# ATSAM4E16C register map
Vendor: Atmel; Series: SAM4E; File version: 0
Atmel ATSAM4E16C Microcontroller
CPU: CM4 r0p1, selectable endian, MPU, FPU, 4 interrupt priority bits
Registers are 32-bit, read-write, reset 0x0 unless marked. A register's access mark holds for its fields unless they carry their own. Offsets are from the block's base; lines under a group give offsets from that group; [hi:lo] are bit positions; {n}, {i} and the like mark numbered series; 'fields as' and 'values as' point back to an identical list; <NAME> marks a mode.

## Memory map
0x40000000 PWM size 0x4000 — Pulse Width Modulation Controller
0x40004000 AES size 0x4000 — Advanced Encryption Standard
0x4000D000 MPU size 0x830 — Memory Protection Unit (MPU)
0x40010000 CAN0 size 0x4000 — Controller Area Network 0
0x40034000 GMAC size 0x4000 — Gigabit Ethernet MAC
0x40060600 UART1 size 0x200 — Universal Asynchronous Receiver Transmitter 1
0x40080000 HSMCI size 0x4000 — High Speed MultiMedia Card Interface
0x40084000 UDP size 0x4000 — USB Device Port
0x40088000 SPI size 0x4000 — Serial Peripheral Interface
0x40090000 TC0 size 0x4000 — Timer Counter 0
0x400A0000 USART0 size 0x4000 — Universal Synchronous Asynchronous Receiver Transmitter 0
0x400A4000 USART1 size 0x4000 — Universal Synchronous Asynchronous Receiver Transmitter 1
0x400A8000 TWI0 size 0x8000 — Two-wire Interface 0
0x400AC000 TWI1 size 0x8000 — Two-wire Interface 1
0x400B0000 AFEC0 size 0x4000 — Analog-Front-End Controller 0
0x400B4000 AFEC1 size 0x4000 — Analog-Front-End Controller 1
0x400B8000 DACC size 0x4000 — Digital-to-Analog Converter Controller
0x400BC000 ACC size 0x4000 — Analog Comparator Controller
0x400C0000 DMAC size 0x4000 — DMA Controller
0x400C4000 CMCC size 0x4000 — Cortex M Cache Controller
0x400E0200 MATRIX size 0x200 — AHB Bus Matrix
0x400E0400 PMC size 0x140 — Power Management Controller
0x400E0600 UART0 size 0x128 — Universal Asynchronous Receiver Transmitter 0
0x400E0740 CHIPID size 0x200 — Chip Identifier
0x400E0A00 EFC size 0x200 — Embedded Flash Controller
0x400E0E00 PIOA size 0x200 — Parallel Input/Output Controller A
0x400E1000 PIOB size 0x200 — Parallel Input/Output Controller B
0x400E1400 PIOD size 0x200 — Parallel Input/Output Controller D
0x400E1800 RSTC size 0x200 — Reset Controller
0x400E1810 SUPC size 0x200 — Supply Controller
0x400E1830 RTT size 0x200 — Real-time Timer
0x400E1850 WDT size 0x200 — Watchdog Timer
0x400E1860 RTC size 0x200 — Real-time Clock
0x400E1890 GPBR size 0x200 — General Purpose Backup Registers
0x400E1900 RSWDT size 0x200 — Reinforced Safety Watchdog Timer
0xE000E000 SCB blocks up to offset 0xD40 — System Control Block (SCB)
0xE000E010 SYST size 0x10 — System timer, SysTick
0xE000E100 NVIC size 0xE04 — Nested Vectored Interrupt Controller (NVIC)
0xE000EF34 FPU size 0x10 — Floating Point Unit (FPU)

## Interrupts
3 INT_Hard_Fault (SCB)
4 INT_Mem_Manage_Fault (SCB)
5 INT_Bus_Fault (SCB)
5 PMC
6 EFC
6 INT_Usage_Fault (SCB)
7 UART0
9 PIOA
10 PIOB
11 INT_SVCall (SCB)
12 PIOD
14 INT_PendableSrvReq (SCB)
14 USART0
15 INT_SysTick (SYST)
15 USART1
16 HSMCI
17 TWI0
18 TWI1
19 SPI
20 DMAC
21 TC0
22 TC1 (TC0)
23 TC2 (TC0)
30 AFEC0
31 AFEC1
32 DACC
33 ACC
35 UDP
36 PWM
37 CAN0
39 AES
44 GMAC
45 UART1

## AES — Advanced Encryption Standard
Base 0x40004000; register names take the prefix AES_
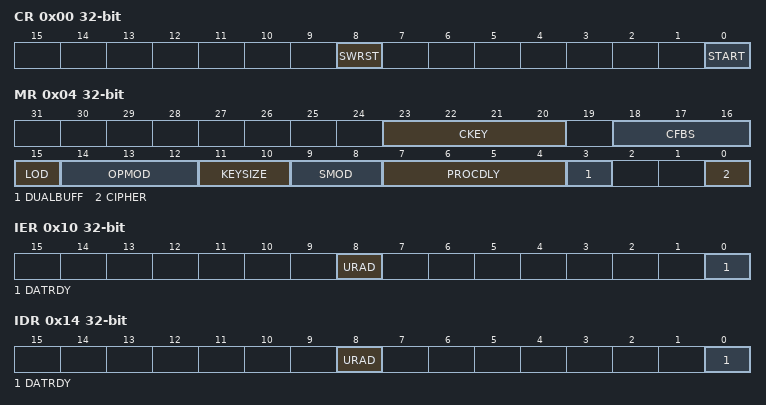
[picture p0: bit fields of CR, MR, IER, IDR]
0x00 CR wo reset not defined — Control Register
  [8] SWRST — Software Reset
  [0] START — Start Processing
0x04 MR — Mode Register
  [23:20] CKEY — Key
    14=PASSWD (This field must be written with 0xE the first time that AES_MR is programmed. For subsequent programming of the AES_MR register, any value can be written, including that of 0xE.Always reads as 0.)
  [18:16] CFBS — Cipher Feedback Data Size
    0=SIZE_128BIT (128-bit); 1=SIZE_64BIT (64-bit); 2=SIZE_32BIT (32-bit); 3=SIZE_16BIT (16-bit); 4=SIZE_8BIT (8-bit)
  [15] LOD — Last Output Data Mode
  [14:12] OPMOD — Operation Mode
    0=ECB (ECB: Electronic Code Book mode); 1=CBC (CBC: Cipher Block Chaining mode); 2=OFB (OFB: Output Feedback mode); 3=CFB (CFB: Cipher Feedback mode); 4=CTR (CTR: Counter mode (16-bit internal counter))
  [11:10] KEYSIZE
    0=AES128 (AES Key Size is 128 bits); 1=AES192 (AES Key Size is 192 bits); 2=AES256 (AES Key Size is 256 bits)
  [9:8] SMOD — Start Mode
    0=MANUAL_START (Manual Mode); 1=AUTO_START (Auto Mode); 2=IDATAR0_START (AES_IDATAR0 access only Auto Mode)
  [7:4] PROCDLY — Processing Delay
  [3] DUALBUFF — Dual Input BUFFer
    0=INACTIVE (AES_IDATARx cannot be written during processing of previous block.); 1=ACTIVE (AES_IDATARx can be written during processing of previous block when SMOD = 0x2. It speeds up the overall runtime of large files.)
  [0] CIPHER — Processing Mode
0x10 IER wo reset not defined — Interrupt Enable Register
  [8] URAD — Unspecified Register Access Detection Interrupt Enable
  [0] DATRDY — Data Ready Interrupt Enable
0x14 IDR wo reset not defined — Interrupt Disable Register
  [8] URAD — Unspecified Register Access Detection Interrupt Disable
  [0] DATRDY — Data Ready Interrupt Disable
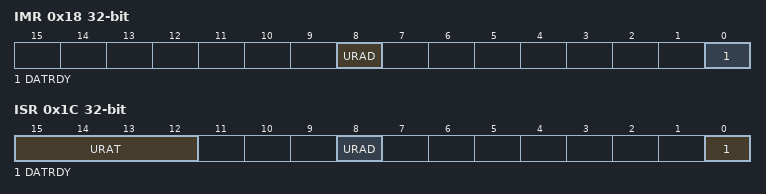
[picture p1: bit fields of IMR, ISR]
0x18 IMR ro — Interrupt Mask Register
  [8] URAD — Unspecified Register Access Detection Interrupt Mask
  [0] DATRDY — Data Ready Interrupt Mask
0x1C ISR ro — Interrupt Status Register
  [15:12] URAT — Unspecified Register Access:
    0=IDR_WR_PROCESSING (Input Data Register written during the data processing when SMOD=0x2 mode.); 1=ODR_RD_PROCESSING (Output Data Register read during the data processing.); 2=MR_WR_PROCESSING (Mode Register written during the data processing.); 3=ODR_RD_SUBKGEN (Output Data Register read during the sub-keys generation.); 4=MR_WR_SUBKGEN (Mode Register written during the sub-keys generation.); 5=WOR_RD_ACCESS (Write-only register read access.)
  [8] URAD — Unspecified Register Access Detection Status
  [0] DATRDY — Data Ready
{0x20+4i} KEYWR[{i}] (i=0..7) wo reset not defined — Key Word Register
  [31:0] KEYW — Key Word
{0x40+4i} IDATAR[{i}] (i=0..3) wo reset not defined — Input Data Register
  [31:0] IDATA — Input Data Word
{0x50+4i} ODATAR[{i}] (i=0..3) ro reset not defined — Output Data Register
  [31:0] ODATA — Output Data
{0x60+4i} IVR[{i}] (i=0..3) wo reset not defined — Initialization Vector Register
  [31:0] IV — Initialization Vector

## Notices in the file
SAM Software Package License
Copyright (c) 2013, Atmel Corporation
All rights reserved.
Redistribution and use in source and binary forms, with or without
modification, are permitted provided that the following condition is met:
- Redistributions of source code must retain the above copyright notice,
this list of conditions and the disclaimer below.
Atmel's name may not be used to endorse or promote products derived from
this software without specific prior written permission.
DISCLAIMER:  THIS SOFTWARE IS PROVIDED BY ATMEL "AS IS" AND ANY EXPRESS OR
IMPLIED WARRANTIES, INCLUDING, BUT NOT LIMITED TO, THE IMPLIED WARRANTIES OF
MERCHANTABILITY, FITNESS FOR A PARTICULAR PURPOSE AND NON-INFRINGEMENT ARE
DISCLAIMED. IN NO EVENT SHALL ATMEL BE LIABLE FOR ANY DIRECT, INDIRECT,
INCIDENTAL, SPECIAL, EXEMPLARY, OR CONSEQUENTIAL DAMAGES (INCLUDING, BUT NOT
LIMITED TO, PROCUREMENT OF SUBSTITUTE GOODS OR SERVICES; LOSS OF USE, DATA,
OR PROFITS; OR BUSINESS INTERRUPTION) HOWEVER CAUSED AND ON ANY THEORY OF
LIABILITY, WHETHER IN CONTRACT, STRICT LIABILITY, OR TORT (INCLUDING
NEGLIGENCE OR OTHERWISE) ARISING IN ANY WAY OUT OF THE USE OF THIS SOFTWARE,
EVEN IF ADVISED OF THE POSSIBILITY OF SUCH DAMAGE.
